# CBASS_INFRA_CBASS_FW_45020000h register map
Vendor: Texas Instruments
Peripheral module from a debugger description file (folder AM275x).
Registers are 32-bit, read-write, reset 0x0 unless marked. A register's access mark holds for its fields unless they carry their own. Offsets are as the file gives them; lines under a group give offsets from that group; [hi:lo] are bit positions; {n}, {i} and the like mark numbered series; 'fields as' and 'values as' point back to an identical list; <NAME> marks a mode.

## cbass_fw
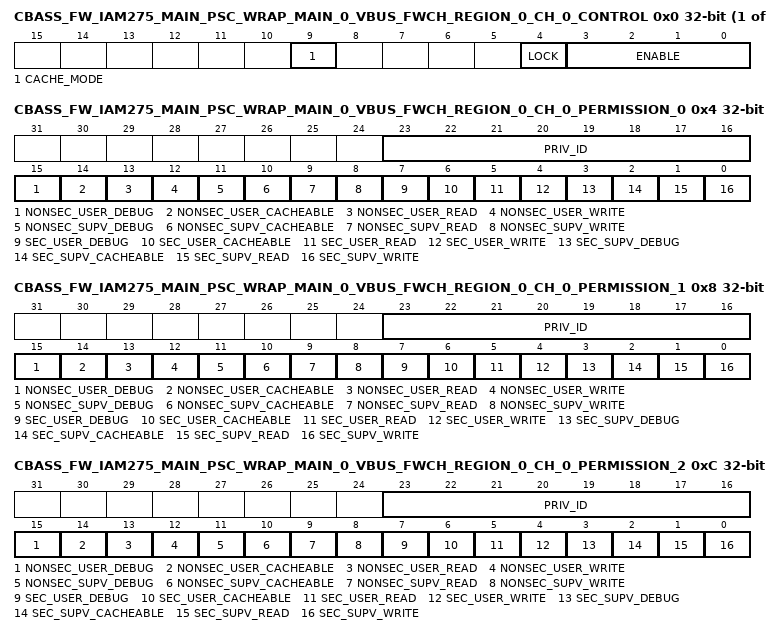
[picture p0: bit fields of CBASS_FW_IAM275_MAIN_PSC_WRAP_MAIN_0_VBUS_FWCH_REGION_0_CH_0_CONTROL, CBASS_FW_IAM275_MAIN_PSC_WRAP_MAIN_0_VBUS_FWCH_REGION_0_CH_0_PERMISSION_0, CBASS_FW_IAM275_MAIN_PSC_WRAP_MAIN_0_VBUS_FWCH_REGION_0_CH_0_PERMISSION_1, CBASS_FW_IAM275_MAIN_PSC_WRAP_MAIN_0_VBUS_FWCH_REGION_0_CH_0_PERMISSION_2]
{0x0+0x20*i} CBASS_FW_IAM275_MAIN_PSC_WRAP_MAIN_0_VBUS_FWCH_REGION_{i}_CH_0_CONTROL access not given (i=0..4) — The FW Region {i} Channel 0 Control Register defines the control fields for the target Iam275_main_psc_wrap_main_0.vbus region {i} channel 0 firewall.
  [9] CACHE_MODE rw — Cache mode for region. Set to 1 to check cache permissions. Set to 0 to ignore cache permissions. Reset Source: domain_default_rst_mod_g_rst_n
  [4] LOCK — Lock region. Once set region values cannot be modified. Reset Source: domain_default_rst_mod_g_rst_n (access R/W1TS)
  [3:0] ENABLE rw — Enable region. A value of 0xA enables, others disable. Reset Source: domain_default_rst_mod_g_rst_n
{0x4+0x20*i} CBASS_FW_IAM275_MAIN_PSC_WRAP_MAIN_0_VBUS_FWCH_REGION_{i}_CH_0_PERMISSION_0 (i=0..4) — The FW Region {i} Channel 0 Permission 0 Register defines the permissions for the target Iam275_main_psc_wrap_main_0.vbus region {i} channel 0 firewall.
  [23:16] PRIV_ID — Allowed privid. Reset Source: domain_default_rst_mod_g_rst_n
  [15] NONSEC_USER_DEBUG — Non-secure user debug allowed. Reset Source: domain_default_rst_mod_g_rst_n
  [14] NONSEC_USER_CACHEABLE — Non-secure user cacheable allowed. Reset Source: domain_default_rst_mod_g_rst_n
  [13] NONSEC_USER_READ — Non-secure user read allowed. Reset Source: domain_default_rst_mod_g_rst_n
  [12] NONSEC_USER_WRITE — Non-secure user write allowed. Reset Source: domain_default_rst_mod_g_rst_n
  [11] NONSEC_SUPV_DEBUG — Non-secure supervisor debug allowed. Reset Source: domain_default_rst_mod_g_rst_n
  [10] NONSEC_SUPV_CACHEABLE — Non-secure supervisor cacheable allowed. Reset Source: domain_default_rst_mod_g_rst_n
  [9] NONSEC_SUPV_READ — Non-secure supervisor read allowed. Reset Source: domain_default_rst_mod_g_rst_n
  [8] NONSEC_SUPV_WRITE — Non-secure supervisor write allowed. Reset Source: domain_default_rst_mod_g_rst_n
  [7] SEC_USER_DEBUG — Secure user debug allowed. Reset Source: domain_default_rst_mod_g_rst_n
  [6] SEC_USER_CACHEABLE — Secure user cacheable allowed. Reset Source: domain_default_rst_mod_g_rst_n
  [5] SEC_USER_READ — Secure user read allowed. Reset Source: domain_default_rst_mod_g_rst_n
  [4] SEC_USER_WRITE — Secure user write allowed. Reset Source: domain_default_rst_mod_g_rst_n
  [3] SEC_SUPV_DEBUG — Secure supervisor debug allowed. Reset Source: domain_default_rst_mod_g_rst_n
  [2] SEC_SUPV_CACHEABLE — Secure supervisor cacheable allowed. Reset Source: domain_default_rst_mod_g_rst_n
  [1] SEC_SUPV_READ — Secure supervisor read allowed. Reset Source: domain_default_rst_mod_g_rst_n
  [0] SEC_SUPV_WRITE — Secure supervisor write allowed. Reset Source: domain_default_rst_mod_g_rst_n
{0x8+0x20*i} CBASS_FW_IAM275_MAIN_PSC_WRAP_MAIN_0_VBUS_FWCH_REGION_{i}_CH_0_PERMISSION_1 (i=0..4) — The FW Region {i} Channel 0 Permission 1 Register defines the permissions for the target Iam275_main_psc_wrap_main_0.vbus region {i} channel 0 firewall.
  fields as CBASS_FW_IAM275_MAIN_PSC_WRAP_MAIN_0_VBUS_FWCH_REGION_0_CH_0_PERMISSION_0
{0xC+0x20*i} CBASS_FW_IAM275_MAIN_PSC_WRAP_MAIN_0_VBUS_FWCH_REGION_{i}_CH_0_PERMISSION_2 (i=0..4) — The FW Region {i} Channel 0 Permission 2 Register defines the permissions for the target Iam275_main_psc_wrap_main_0.vbus region {i} channel 0 firewall.
  fields as CBASS_FW_IAM275_MAIN_PSC_WRAP_MAIN_0_VBUS_FWCH_REGION_0_CH_0_PERMISSION_0
